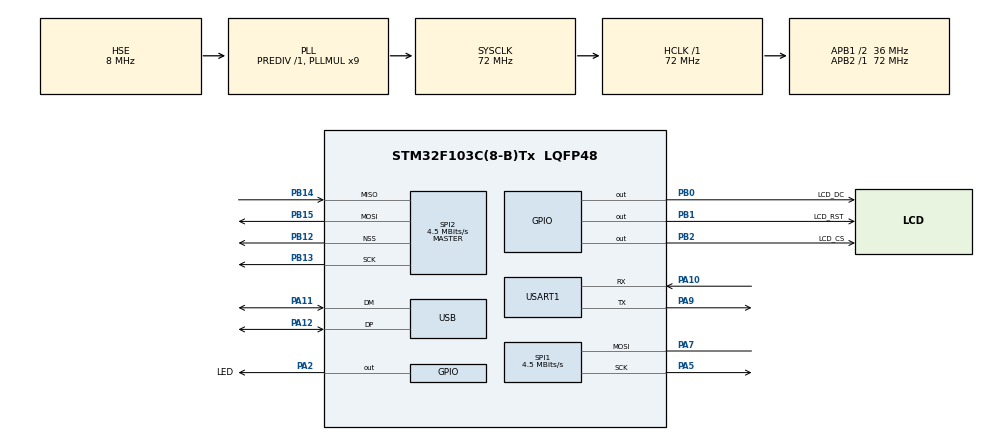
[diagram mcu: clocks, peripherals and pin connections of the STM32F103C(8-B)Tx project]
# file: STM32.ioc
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FREERTOS.Tasks01=defaultTask,24,128,StartDefaultTask,Default,NULL,Dynamic,NULL,NULL;task1,8,128,StartTask02,Default,NULL,Dynamic,NULL,NULL;task2,8,128,StartTask03,Default,NULL,Dynamic,NULL,NULL
FREERTOS.Timers01=myTimer01,Callback01,osTimerPeriodic,Default,NULL,Dynamic,NULL
Mcu.Family=STM32F1
Mcu.Name=STM32F103C(8-B)Tx
Mcu.Package=LQFP48
NVIC.PriorityGroup=NVIC_PRIORITYGROUP_4
NVIC.TIM1_UP_IRQn=true\:0\:0\:false\:false\:true\:false\:false\:true
NVIC.TimeBase=TIM1_UP_IRQn
NVIC.TimeBaseIP=TIM1
PA10.Mode=Asynchronous
PA10.Signal=USART1_RX
PA11.Mode=Device
PA11.Signal=USB_DM
PA12.Mode=Device
PA12.Signal=USB_DP
PA13.Mode=Serial_Wire
PA13.Signal=SYS_JTMS-SWDIO
PA14.Mode=Serial_Wire
PA14.Signal=SYS_JTCK-SWCLK
PA2.GPIO_Label=LED
PA2.Signal=GPIO_Output
PA5.Mode=Simplex_Bidirectional_Master
PA5.Signal=SPI1_SCK
PA7.Mode=Simplex_Bidirectional_Master
PA7.Signal=SPI1_MOSI
PA9.Mode=Asynchronous
PA9.Signal=USART1_TX
PB0.GPIO_Label=LCD_DC
PB0.Signal=GPIO_Output
PB1.GPIO_Label=LCD_RST
PB1.Signal=GPIO_Output
PB12.Mode=NSS_Signal_Hard_Output
PB12.Signal=SPI2_NSS
PB13.Mode=Full_Duplex_Master
PB13.Signal=SPI2_SCK
PB14.Mode=Full_Duplex_Master
PB14.Signal=SPI2_MISO
PB15.Mode=Full_Duplex_Master
PB15.Signal=SPI2_MOSI
PB2.GPIO_Label=LCD_CS
PB2.Signal=GPIO_Output
PD0-OSC_IN.Mode=HSE-External-Oscillator
PD0-OSC_IN.Signal=RCC_OSC_IN
PD1-OSC_OUT.Mode=HSE-External-Oscillator
PD1-OSC_OUT.Signal=RCC_OSC_OUT
ProjectManager.HeapSize=0x200
ProjectManager.StackSize=0x400
ProjectManager.TargetToolchain=MDK-ARM V5.27
RCC.AHBFreq_Value=72000000
RCC.APB1CLKDivider=RCC_HCLK_DIV2
RCC.APB1Freq_Value=36000000
RCC.APB1TimFreq_Value=72000000
RCC.APB2Freq_Value=72000000
RCC.APB2TimFreq_Value=72000000
RCC.EnbaleCSS=true
RCC.HCLKFreq_Value=72000000
RCC.PLLMUL=RCC_PLL_MUL9
RCC.SYSCLKFreq_VALUE=72000000
RCC.SYSCLKSource=RCC_SYSCLKSOURCE_PLLCLK
RCC.USBFreq_Value=48000000
RCC.USBPrescaler=RCC_USBCLKSOURCE_PLL_DIV1_5
SPI1.BaudRatePrescaler=SPI_BAUDRATEPRESCALER_16
SPI1.CalculateBaudRate=4.5 MBits/s
SPI1.Direction=SPI_DIRECTION_1LINE
SPI1.Mode=SPI_MODE_MASTER
SPI1.VirtualType=VM_MASTER
SPI2.BaudRatePrescaler=SPI_BAUDRATEPRESCALER_8
SPI2.CalculateBaudRate=4.5 MBits/s
SPI2.Direction=SPI_DIRECTION_2LINES
SPI2.Mode=SPI_MODE_MASTER
SPI2.VirtualNSS=VM_NSSHARD
SPI2.VirtualType=VM_MASTER
USART1.VirtualMode=VM_ASYNC
VP_FREERTOS_VS_CMSIS_V2.Mode=CMSIS_V2
VP_SYS_VS_tim1.Mode=TIM1
board=custom

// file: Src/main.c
/* USER CODE BEGIN Header */
/**
  ******************************************************************************
  * @file           : main.c
  * @brief          : Main program body
  ******************************************************************************
  * @attention
  *
  * <h2><center>&copy; Copyright (c) 2021 STMicroelectronics.
  * All rights reserved.</center></h2>
  *
  * This software component is licensed by ST under BSD 3-Clause license,
  * the "License"; You may not use this file except in compliance with the
  * License. You may obtain a copy of the License at:
  *                        opensource.org/licenses/BSD-3-Clause
  *
  ******************************************************************************
  */
/* USER CODE END Header */

#include "main.h"
#include "cmsis_os.h"

SPI_HandleTypeDef hspi1;
SPI_HandleTypeDef hspi2;

UART_HandleTypeDef huart1;

PCD_HandleTypeDef hpcd_USB_FS;

/* Definitions for defaultTask */
osThreadId_t defaultTaskHandle;
const osThreadAttr_t defaultTask_attributes = {
  .name = "defaultTask",
  .priority = (osPriority_t) osPriorityNormal,
  .stack_size = 128
};
/* Definitions for task1 */
osThreadId_t task1Handle;
const osThreadAttr_t task1_attributes = {
  .name = "task1",
  .priority = (osPriority_t) osPriorityLow,
  .stack_size = 128
};
/* Definitions for task2 */
osThreadId_t task2Handle;
const osThreadAttr_t task2_attributes = {
  .name = "task2",
  .priority = (osPriority_t) osPriorityLow,
  .stack_size = 128
};
/* Definitions for myTimer01 */
osTimerId_t myTimer01Handle;
const osTimerAttr_t myTimer01_attributes = {
  .name = "myTimer01"
};

void SystemClock_Config(void);
static void MX_GPIO_Init(void);
static void MX_SPI1_Init(void);
static void MX_SPI2_Init(void);
static void MX_USART1_UART_Init(void);
static void MX_USB_PCD_Init(void);
void StartDefaultTask(void *argument);
void StartTask02(void *argument);
void StartTask03(void *argument);
void Callback01(void *argument);

int main(void)
{

  /* MCU Configuration--------------------------------------------------------*/

  /* Reset of all peripherals, Initializes the Flash interface and the Systick. */
  HAL_Init();

  /* Configure the system clock */
  SystemClock_Config();

  /* Initialize all configured peripherals */
  MX_GPIO_Init();
  MX_SPI1_Init();
  MX_SPI2_Init();
  MX_USART1_UART_Init();
  MX_USB_PCD_Init();
  /* Init scheduler */
  osKernelInitialize();

  /* Create the timer(s) */
  /* creation of myTimer01 */
  myTimer01Handle = osTimerNew(Callback01, osTimerPeriodic, NULL, &myTimer01_attributes);

  /* Create the thread(s) */
  /* creation of defaultTask */
  defaultTaskHandle = osThreadNew(StartDefaultTask, NULL, &defaultTask_attributes);

  /* creation of task1 */
  task1Handle = osThreadNew(StartTask02, NULL, &task1_attributes);

  /* creation of task2 */
  task2Handle = osThreadNew(StartTask03, NULL, &task2_attributes);

  /* Start scheduler */
  osKernelStart();

  /* We should never get here as control is now taken by the scheduler */

  /* Infinite loop */
  while (1)
  {

  }
}

void SystemClock_Config(void)
{
  RCC_OscInitTypeDef RCC_OscInitStruct = {0};
  RCC_ClkInitTypeDef RCC_ClkInitStruct = {0};
  RCC_PeriphCLKInitTypeDef PeriphClkInit = {0};

  /** Initializes the CPU, AHB and APB busses clocks
  */
  RCC_OscInitStruct.OscillatorType = RCC_OSCILLATORTYPE_HSE;
  RCC_OscInitStruct.HSEState = RCC_HSE_ON;
  RCC_OscInitStruct.HSEPredivValue = RCC_HSE_PREDIV_DIV1;
  RCC_OscInitStruct.HSIState = RCC_HSI_ON;
  RCC_OscInitStruct.PLL.PLLState = RCC_PLL_ON;
  RCC_OscInitStruct.PLL.PLLSource = RCC_PLLSOURCE_HSE;
  RCC_OscInitStruct.PLL.PLLMUL = RCC_PLL_MUL9;
  if (HAL_RCC_OscConfig(&RCC_OscInitStruct) != HAL_OK)
  {
    Error_Handler();
  }
  /** Initializes the CPU, AHB and APB busses clocks
  */
  RCC_ClkInitStruct.ClockType = RCC_CLOCKTYPE_HCLK|RCC_CLOCKTYPE_SYSCLK
                              |RCC_CLOCKTYPE_PCLK1|RCC_CLOCKTYPE_PCLK2;
  RCC_ClkInitStruct.SYSCLKSource = RCC_SYSCLKSOURCE_PLLCLK;
  RCC_ClkInitStruct.AHBCLKDivider = RCC_SYSCLK_DIV1;
  RCC_ClkInitStruct.APB1CLKDivider = RCC_HCLK_DIV2;
  RCC_ClkInitStruct.APB2CLKDivider = RCC_HCLK_DIV1;

  if (HAL_RCC_ClockConfig(&RCC_ClkInitStruct, FLASH_LATENCY_2) != HAL_OK)
  {
    Error_Handler();
  }
  PeriphClkInit.PeriphClockSelection = RCC_PERIPHCLK_USB;
  PeriphClkInit.UsbClockSelection = RCC_USBCLKSOURCE_PLL_DIV1_5;
  if (HAL_RCCEx_PeriphCLKConfig(&PeriphClkInit) != HAL_OK)
  {
    Error_Handler();
  }
  /** Enables the Clock Security System
  */
  HAL_RCC_EnableCSS();
}

static void MX_SPI1_Init(void)
{

  /* SPI1 parameter configuration*/
  hspi1.Instance = SPI1;
  hspi1.Init.Mode = SPI_MODE_MASTER;
  hspi1.Init.Direction = SPI_DIRECTION_1LINE;
  hspi1.Init.DataSize = SPI_DATASIZE_8BIT;
  hspi1.Init.CLKPolarity = SPI_POLARITY_LOW;
  hspi1.Init.CLKPhase = SPI_PHASE_1EDGE;
  hspi1.Init.NSS = SPI_NSS_SOFT;
  hspi1.Init.BaudRatePrescaler = SPI_BAUDRATEPRESCALER_16;
  hspi1.Init.FirstBit = SPI_FIRSTBIT_MSB;
  hspi1.Init.TIMode = SPI_TIMODE_DISABLE;
  hspi1.Init.CRCCalculation = SPI_CRCCALCULATION_DISABLE;
  hspi1.Init.CRCPolynomial = 10;
  if (HAL_SPI_Init(&hspi1) != HAL_OK)
  {
    Error_Handler();
  }

}

static void MX_SPI2_Init(void)
{

  /* SPI2 parameter configuration*/
  hspi2.Instance = SPI2;
  hspi2.Init.Mode = SPI_MODE_MASTER;
  hspi2.Init.Direction = SPI_DIRECTION_2LINES;
  hspi2.Init.DataSize = SPI_DATASIZE_8BIT;
  hspi2.Init.CLKPolarity = SPI_POLARITY_LOW;
  hspi2.Init.CLKPhase = SPI_PHASE_1EDGE;
  hspi2.Init.NSS = SPI_NSS_HARD_OUTPUT;
  hspi2.Init.BaudRatePrescaler = SPI_BAUDRATEPRESCALER_8;
  hspi2.Init.FirstBit = SPI_FIRSTBIT_MSB;
  hspi2.Init.TIMode = SPI_TIMODE_DISABLE;
  hspi2.Init.CRCCalculation = SPI_CRCCALCULATION_DISABLE;
  hspi2.Init.CRCPolynomial = 10;
  if (HAL_SPI_Init(&hspi2) != HAL_OK)
  {
    Error_Handler();
  }

}

static void MX_USART1_UART_Init(void)
{

  huart1.Instance = USART1;
  huart1.Init.BaudRate = 115200;
  huart1.Init.WordLength = UART_WORDLENGTH_8B;
  huart1.Init.StopBits = UART_STOPBITS_1;
  huart1.Init.Parity = UART_PARITY_NONE;
  huart1.Init.Mode = UART_MODE_TX_RX;
  huart1.Init.HwFlowCtl = UART_HWCONTROL_NONE;
  huart1.Init.OverSampling = UART_OVERSAMPLING_16;
  if (HAL_UART_Init(&huart1) != HAL_OK)
  {
    Error_Handler();
  }

}

static void MX_USB_PCD_Init(void)
{

  hpcd_USB_FS.Instance = USB;
  hpcd_USB_FS.Init.dev_endpoints = 8;
  hpcd_USB_FS.Init.speed = PCD_SPEED_FULL;
  hpcd_USB_FS.Init.low_power_enable = DISABLE;
  hpcd_USB_FS.Init.lpm_enable = DISABLE;
  hpcd_USB_FS.Init.battery_charging_enable = DISABLE;
  if (HAL_PCD_Init(&hpcd_USB_FS) != HAL_OK)
  {
    Error_Handler();
  }

}

static void MX_GPIO_Init(void)
{
  GPIO_InitTypeDef GPIO_InitStruct = {0};

  /* GPIO Ports Clock Enable */
  __HAL_RCC_GPIOD_CLK_ENABLE();
  __HAL_RCC_GPIOA_CLK_ENABLE();
  __HAL_RCC_GPIOB_CLK_ENABLE();

  /*Configure GPIO pin Output Level */
  HAL_GPIO_WritePin(LED_GPIO_Port, LED_Pin, GPIO_PIN_RESET);

  /*Configure GPIO pin Output Level */
  HAL_GPIO_WritePin(GPIOB, LCD_DC_Pin|LCD_RST_Pin|LCD_CS_Pin, GPIO_PIN_RESET);

  /*Configure GPIO pin : LED_Pin */
  GPIO_InitStruct.Pin = LED_Pin;
  GPIO_InitStruct.Mode = GPIO_MODE_OUTPUT_PP;
  GPIO_InitStruct.Pull = GPIO_NOPULL;
  GPIO_InitStruct.Speed = GPIO_SPEED_FREQ_LOW;
  HAL_GPIO_Init(LED_GPIO_Port, &GPIO_InitStruct);

  /*Configure GPIO pins : LCD_DC_Pin LCD_RST_Pin LCD_CS_Pin */
  GPIO_InitStruct.Pin = LCD_DC_Pin|LCD_RST_Pin|LCD_CS_Pin;
  GPIO_InitStruct.Mode = GPIO_MODE_OUTPUT_PP;
  GPIO_InitStruct.Pull = GPIO_NOPULL;
  GPIO_InitStruct.Speed = GPIO_SPEED_FREQ_LOW;
  HAL_GPIO_Init(GPIOB, &GPIO_InitStruct);

}

void StartDefaultTask(void *argument)
{
  /* USER CODE BEGIN 5 */
  /* Infinite loop */
  for(;;)
  {
    HAL_GPIO_TogglePin(GPIOA, GPIO_PIN_2);
    osDelay(100);
  }
  /* USER CODE END 5 */
}

void StartTask02(void *argument)
{
  for(;;)
  {
    osDelay(1);
  }
}

void StartTask03(void *argument)
{
  for(;;)
  {
    osDelay(1);
  }
}

/* Callback01 function */
void Callback01(void *argument)
{
}

void HAL_TIM_PeriodElapsedCallback(TIM_HandleTypeDef *htim)
{
  if (htim->Instance == TIM1) {
    HAL_IncTick();
  }
}

void Error_Handler(void)
{
}

/************************ (C) COPYRIGHT STMicroelectronics *****END OF FILE****/
